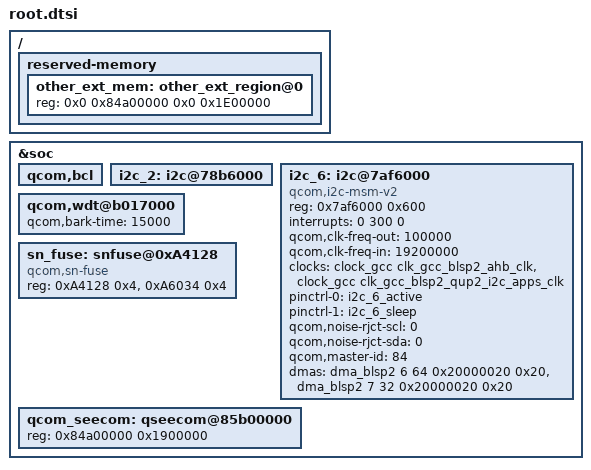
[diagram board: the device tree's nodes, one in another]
/ {
	/* aliases i2c6 */

	reserved-memory {
		other_ext_mem: other_ext_region@0 {
			reg = <0x0 0x84a00000 0x0 0x1E00000>;
		};
	};
};

&soc {
	qcom,bcl {
		/delete-property/ qcom,bcl-enable;
	};

	i2c_2: i2c@78b6000 { /* BLSP1 QUP2 */
		/delete-node/ pericom-type-c@1d;
	};

	i2c_6: i2c@7af6000 {
		compatible = "qcom,i2c-msm-v2";
		#address-cells = <1>;
		#size-cells = <0>;
		reg-names = "qup_phys_addr";
		reg = <0x7af6000 0x600>;
		interrupt-names = "qup_irq";
		interrupts = <0 300 0>;
		qcom,clk-freq-out = <100000>;
		qcom,clk-freq-in  = <19200000>;
		clock-names = "iface_clk", "core_clk";
		clocks = <&clock_gcc clk_gcc_blsp2_ahb_clk>,
			<&clock_gcc clk_gcc_blsp2_qup2_i2c_apps_clk>;

		pinctrl-names = "i2c_active", "i2c_sleep";
		pinctrl-0 = <&i2c_6_active>;
		pinctrl-1 = <&i2c_6_sleep>;
		qcom,noise-rjct-scl = <0>;
		qcom,noise-rjct-sda = <0>;
		qcom,master-id = <84>;
		dmas = <&dma_blsp2 6 64 0x20000020 0x20>,
			<&dma_blsp2 7 32 0x20000020 0x20>;
		dma-names = "tx", "rx";
		status = "ok";
	};

	qcom,wdt@b017000 {
		qcom,bark-time = <15000>;
	};

	sn_fuse: snfuse@0xA4128 {
		compatible = "qcom,sn-fuse";
		reg = <0xA4128 0x4>,
			 <0xA6034 0x4>;
		reg-names = "sn-base","fuse-state";
	};

	qcom_seecom: qseecom@85b00000 {
		reg = <0x84a00000 0x1900000>;
	};
};
